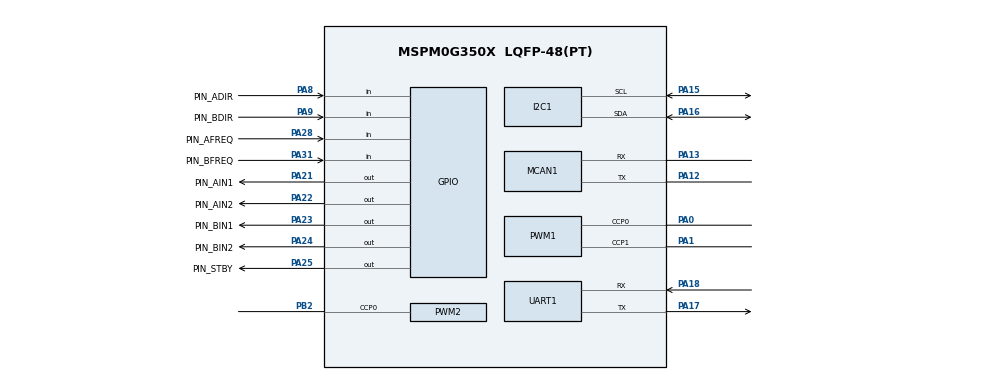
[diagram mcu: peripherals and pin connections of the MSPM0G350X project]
/**
 * @cliArgs --device "MSPM0G350X" --part "Default" --package "LQFP-48(PT)" --product "mspm0_sdk@2.10.00.04"
 * @versions {"tool":"1.27.1+4634"}
 */

/**
 * Import the modules used in this configuration.
 */
const ADC12         = scripting.addModule("/ti/driverlib/ADC12", {}, false);
const ADC121        = ADC12.addInstance();
const Board         = scripting.addModule("/ti/driverlib/Board");
const GPIO          = scripting.addModule("/ti/driverlib/GPIO", {}, false);
const GPIO1         = GPIO.addInstance();
const GPIO2         = GPIO.addInstance();
const I2C           = scripting.addModule("/ti/driverlib/I2C", {}, false);
const I2C1          = I2C.addInstance();
const MCAN          = scripting.addModule("/ti/driverlib/MCAN", {}, false);
const MCAN1         = MCAN.addInstance();
const PWM           = scripting.addModule("/ti/driverlib/PWM", {}, false);
const PWM1          = PWM.addInstance();
const PWM2          = PWM.addInstance();
const SYSCTL        = scripting.addModule("/ti/driverlib/SYSCTL");
const TIMER         = scripting.addModule("/ti/driverlib/TIMER", {}, false);
const TIMER1        = TIMER.addInstance();
const UART          = scripting.addModule("/ti/driverlib/UART", {}, false);
const UART1         = UART.addInstance();
const ProjectConfig = scripting.addModule("/ti/project_config/ProjectConfig");

/**
 * Write custom configuration values to the imported modules.
 */
const divider7       = system.clockTree["PLL_PDIV"];
divider7.divideValue = 2;

const divider9       = system.clockTree["UDIV"];
divider9.divideValue = 2;

const multiplier2         = system.clockTree["PLL_QDIV"];
multiplier2.multiplyValue = 10;

const mux2       = system.clockTree["CANCLKMUX"];
mux2.inputSelect = "CANCLKMUX_PLLCLK1_OUT";

const mux8       = system.clockTree["HSCLKMUX"];
mux8.inputSelect = "HSCLKMUX_SYSPLL0";

ADC121.samplingOperationMode             = "sequence";
ADC121.endAdd                            = 1;
ADC121.repeatMode                        = true;
ADC121.adcMem1chansel                    = "DL_ADC12_INPUT_CHAN_1";
ADC121.$name                             = "ADC_TB6612FNG";
ADC121.adcPin0Config.hideOutputInversion = scripting.forceWrite(false);
ADC121.adcPin0Config.$name               = "ti_driverlib_gpio_GPIOPinGeneric6";
ADC121.peripheral.$assign                = "ADC0";
ADC121.peripheral.adcPin0.$assign        = "PA27";
ADC121.peripheral.adcPin1.$assign        = "PA26";
ADC121.adcPin1Config.hideOutputInversion = scripting.forceWrite(false);
ADC121.adcPin1Config.$name               = "ti_driverlib_gpio_GPIOPinGeneric0";

Board.configureUnused        = true;
Board.unusedDirection        = "INPUT";
Board.unusedInternalResistor = "PULL_DOWN";
Board.genPeriphPinFile       = true;
Board.genResourceCSV         = true;
Board.genFileMod.$name       = "ti_driverlib_BoardPins0";
Board.genFileCSV.$name       = "ti_driverlib_ResourcesCSV0";

GPIO1.$name                          = "GPIO_GRP_TB6612FNG";
GPIO1.port                           = "PORTA";
GPIO1.associatedPins.create(5);
GPIO1.associatedPins[0].$name        = "PIN_AIN1";
GPIO1.associatedPins[0].assignedPin  = "21";
GPIO1.associatedPins[0].pin.$assign  = "PA21";
GPIO1.associatedPins[1].$name        = "PIN_AIN2";
GPIO1.associatedPins[1].assignedPin  = "22";
GPIO1.associatedPins[1].pin.$assign  = "PA22";
GPIO1.associatedPins[2].$name        = "PIN_BIN1";
GPIO1.associatedPins[2].assignedPin  = "23";
GPIO1.associatedPins[2].pin.$assign  = "PA23";
GPIO1.associatedPins[3].$name        = "PIN_BIN2";
GPIO1.associatedPins[3].assignedPin  = "24";
GPIO1.associatedPins[3].pin.$assign  = "PA24";
GPIO1.associatedPins[4].$name        = "PIN_STBY";
GPIO1.associatedPins[4].initialValue = "SET";
GPIO1.associatedPins[4].assignedPin  = "25";
GPIO1.associatedPins[4].pin.$assign  = "PA25";

GPIO2.port                                = "PORTA";
GPIO2.$name                               = "GPIO_GRP_MOTOR";
GPIO2.associatedPins.create(4);
GPIO2.associatedPins[0].$name             = "PIN_ADIR";
GPIO2.associatedPins[0].direction         = "INPUT";
GPIO2.associatedPins[0].assignedPin       = "8";
GPIO2.associatedPins[0].internalResistor  = "PULL_UP";
GPIO2.associatedPins[0].pin.$assign       = "PA8";
GPIO2.associatedPins[1].$name             = "PIN_BDIR";
GPIO2.associatedPins[1].direction         = "INPUT";
GPIO2.associatedPins[1].assignedPin       = "9";
GPIO2.associatedPins[1].internalResistor  = "PULL_UP";
GPIO2.associatedPins[1].pin.$assign       = "PA9";
GPIO2.associatedPins[2].direction         = "INPUT";
GPIO2.associatedPins[2].$name             = "PIN_AFREQ";
GPIO2.associatedPins[2].internalResistor  = "PULL_UP";
GPIO2.associatedPins[2].interruptEn       = true;
GPIO2.associatedPins[2].interruptPriority = "3";
GPIO2.associatedPins[2].polarity          = "RISE";
GPIO2.associatedPins[2].assignedPin       = "28";
GPIO2.associatedPins[2].pin.$assign       = "PA28";
GPIO2.associatedPins[3].$name             = "PIN_BFREQ";
GPIO2.associatedPins[3].direction         = "INPUT";
GPIO2.associatedPins[3].internalResistor  = "PULL_UP";
GPIO2.associatedPins[3].interruptEn       = true;
GPIO2.associatedPins[3].interruptPriority = "3";
GPIO2.associatedPins[3].polarity          = "RISE";
GPIO2.associatedPins[3].assignedPin       = "31";
GPIO2.associatedPins[3].pin.$assign       = "PA31";

I2C1.$name                             = "I2C_DRIVERBOARD";
I2C1.peripheral.$assign                = "I2C1";
I2C1.peripheral.sdaPin.$assign         = "PA16";
I2C1.peripheral.sclPin.$assign         = "PA15";
I2C1.sdaPinConfig.hideOutputInversion  = scripting.forceWrite(false);
I2C1.sdaPinConfig.onlyInternalResistor = scripting.forceWrite(false);
I2C1.sdaPinConfig.passedPeripheralType = scripting.forceWrite("Digital");
I2C1.sdaPinConfig.$name                = "ti_driverlib_gpio_GPIOPinGeneric10";
I2C1.sclPinConfig.hideOutputInversion  = scripting.forceWrite(false);
I2C1.sclPinConfig.onlyInternalResistor = scripting.forceWrite(false);
I2C1.sclPinConfig.passedPeripheralType = scripting.forceWrite("Digital");
I2C1.sclPinConfig.$name                = "ti_driverlib_gpio_GPIOPinGeneric11";

MCAN1.$name                            = "CAN_DRIVERBOARD";
MCAN1.peripheral.$assign               = "CANFD0";
MCAN1.peripheral.rxPin.$assign         = "PA13";
MCAN1.peripheral.txPin.$assign         = "PA12";
MCAN1.txPinConfig.direction            = scripting.forceWrite("OUTPUT");
MCAN1.txPinConfig.hideOutputInversion  = scripting.forceWrite(false);
MCAN1.txPinConfig.onlyInternalResistor = scripting.forceWrite(false);
MCAN1.txPinConfig.passedPeripheralType = scripting.forceWrite("Digital");
MCAN1.txPinConfig.$name                = "ti_driverlib_gpio_GPIOPinGeneric1";
MCAN1.rxPinConfig.hideOutputInversion  = scripting.forceWrite(false);
MCAN1.rxPinConfig.onlyInternalResistor = scripting.forceWrite(false);
MCAN1.rxPinConfig.passedPeripheralType = scripting.forceWrite("Digital");
MCAN1.rxPinConfig.$name                = "ti_driverlib_gpio_GPIOPinGeneric7";

PWM1.$name                              = "PWM_TB6612FNG";
PWM1.pwmMode                            = "EDGE_ALIGN_UP";
PWM1.clockPrescale                      = 8;
PWM1.enableShadowLoad                   = true;
PWM1.peripheral.$assign                 = "TIMA0";
PWM1.peripheral.ccp0Pin.$assign         = "PA0";
PWM1.peripheral.ccp1Pin.$assign         = "PA1";
PWM1.PWM_CHANNEL_0.$name                = "ti_driverlib_pwm_PWMTimerCC0";
PWM1.PWM_CHANNEL_0.dutyCycle            = 10;
PWM1.PWM_CHANNEL_1.$name                = "ti_driverlib_pwm_PWMTimerCC1";
PWM1.PWM_CHANNEL_1.dutyCycle            = 10;
PWM1.ccp0PinConfig.direction            = scripting.forceWrite("OUTPUT");
PWM1.ccp0PinConfig.hideOutputInversion  = scripting.forceWrite(false);
PWM1.ccp0PinConfig.onlyInternalResistor = scripting.forceWrite(false);
PWM1.ccp0PinConfig.passedPeripheralType = scripting.forceWrite("Digital");
PWM1.ccp0PinConfig.$name                = "ti_driverlib_gpio_GPIOPinGeneric2";
PWM1.ccp1PinConfig.direction            = scripting.forceWrite("OUTPUT");
PWM1.ccp1PinConfig.hideOutputInversion  = scripting.forceWrite(false);
PWM1.ccp1PinConfig.onlyInternalResistor = scripting.forceWrite(false);
PWM1.ccp1PinConfig.passedPeripheralType = scripting.forceWrite("Digital");
PWM1.ccp1PinConfig.$name                = "ti_driverlib_gpio_GPIOPinGeneric3";

PWM2.$name                              = "PWM_SERVO";
PWM2.ccIndex                            = [0];
PWM2.pwmMode                            = "EDGE_ALIGN_UP";
PWM2.clockPrescale                      = 80;
PWM2.timerCount                         = 20000;
PWM2.PWM_CHANNEL_0.$name                = "ti_driverlib_pwm_PWMTimerCC2";
PWM2.PWM_CHANNEL_0.dutyCycle            = 7.5;
PWM2.ccp0PinConfig.direction            = scripting.forceWrite("OUTPUT");
PWM2.ccp0PinConfig.hideOutputInversion  = scripting.forceWrite(false);
PWM2.ccp0PinConfig.onlyInternalResistor = scripting.forceWrite(false);
PWM2.ccp0PinConfig.passedPeripheralType = scripting.forceWrite("Digital");
PWM2.ccp0PinConfig.$name                = "ti_driverlib_gpio_GPIOPinGeneric12";
PWM2.peripheral.$assign                 = "TIMG6";
PWM2.peripheral.ccp0Pin.$assign         = "PB2";

SYSCTL.clockTreeEn = true;

TIMER1.$name              = "TIMER_0";
TIMER1.timerMode          = "PERIODIC_UP";
TIMER1.timerPeriod        = "50 s";
TIMER1.interrupts         = ["LOAD"];
TIMER1.interruptPriority  = "3";
TIMER1.peripheral.$assign = "TIMG12";

UART1.$name                            = "UART_DRIVERBOARD";
UART1.targetBaudRate                   = 115200;
UART1.peripheral.$assign               = "UART1";
UART1.peripheral.rxPin.$assign         = "PA18";
UART1.peripheral.txPin.$assign         = "PA17";
UART1.txPinConfig.direction            = scripting.forceWrite("OUTPUT");
UART1.txPinConfig.hideOutputInversion  = scripting.forceWrite(false);
UART1.txPinConfig.onlyInternalResistor = scripting.forceWrite(false);
UART1.txPinConfig.passedPeripheralType = scripting.forceWrite("Digital");
UART1.txPinConfig.$name                = "ti_driverlib_gpio_GPIOPinGeneric8";
UART1.rxPinConfig.hideOutputInversion  = scripting.forceWrite(false);
UART1.rxPinConfig.onlyInternalResistor = scripting.forceWrite(false);
UART1.rxPinConfig.passedPeripheralType = scripting.forceWrite("Digital");
UART1.rxPinConfig.$name                = "ti_driverlib_gpio_GPIOPinGeneric9";

ProjectConfig.compiler    = "gcc";
ProjectConfig.genLibIQ    = true;
ProjectConfig.genLibCMSIS = true;

/**
 * Pinmux solution for unlocked pins/peripherals. This ensures that minor changes to the automatic solver in a future
 * version of the tool will not impact the pinmux you originally saw.  These lines can be completely deleted in order to
 * re-solve from scratch.
 */
Board.peripheral.$suggestSolution          = "DEBUGSS";
Board.peripheral.swclkPin.$suggestSolution = "PA20";
Board.peripheral.swdioPin.$suggestSolution = "PA19";
